# SN32F290 register map
Vendor: SONIX; File version: 2026.10.03
CPU: CM0 r0p0, little endian, no MPU, no FPU, 2 interrupt priority bits
Registers are 32-bit, read-write, reset 0x0 unless marked. A register's access mark holds for its fields unless they carry their own. Offsets are from the block's base; [hi:lo] are bit positions; {n}, {i} and the like mark numbered series; 'fields as' and 'values as' point back to an identical list.

## SN_EBI — External Bus Interface
Base 0x40036000
0x00 CTRL reset 0xF00000 (reset mask 0xFFFFFFF) — Offset:0x0 EBI Control Register
  [2n+48:n+24] BK8080MODE{n} (n=0..3) — Bank{n} 8080 Mode
    0=A1D16_4 (A1D16 mode); 1=A1D8_2 (A1D8 mode)
  [43:20] IDLETIME — Bus idle time
    0=No_58 (No Idle time); {v}=V_{v}T (Idle time={v}*PCLK) (v=1..15)
  [2n+32:n+16] ARDY{n}EN (n=0..3) — ARDY of bank {n} enable bit
    0=Disable_434 (Disable bank {n} ARDY function); 1=Enable_145 (Enable bank {n} ARDY function)
  [2n+24:n+12] BC{n}EN (n=0..3) — Byte control of bank {n} enable bit
    0=Disable_434 (Disable byte control of bank {n}); 1=Enable_145 (Enable byte control of bank {n})
  [2n+16:n+8] BANK{n}EN (n=0..3) — EBI bank {n} enable bit
    0=Disable_434 (Disable bank {n}); 1=Enable_145 (Enable bank {n})
  [4n+1:2n] MODE{n} (n=0..3) — EBI bank {n} access mode
    0=AnD8_4 (AnD8 mode); 1=AnD16_4 (AnD16 mode); 2=AnD16ALE_2 (AnD16ALE mode); 3=V_8080_2 (8080 mode)
0x04 ALCTRL (reset mask 0xFFFF) — Offset:0x4 EBI Address Latch Control Register
  [8n+3:4n] AL{n} (n=0..3) — Bank {n} address length=AL{n}+16
    0=V_0000b_19 (AL{n}=0); 1=V_0001b_14 (AL{n}=1); 10=V_1010b_2 (AL{n}=10); 11=V_1011b_18 (AL{n}=10); 12=V_1100b_24 (AL{n}=10); 13=V_1101b (AL{n}=10); 14=V_1110b_12 (AL{n}=10); 15=V_1111b_28 (AL{n}=10); 2=V_0010b_12 (AL{n}=2); 3=V_0011b_12 (AL{n}=3); 4=V_0100b_7 (AL{n}=4); 5=V_0101b_14 (AL{n}=5); 6=V_0110b_4 (AL{n}=6); 7=V_0111b_5 (AL{n}=7); 8=V_1000b_17 (AL{n}=8); 9=V_1001b (AL{n}=9)
0x08 STATUS reset 0x10 (reset mask 0x111) — Offset:0x8 EBI Status Register
  [16:8] EBINSRST — EBI State machine reset
    0=Normal_2 (Normal mode); 1=Reset_V (Reset EBI state machine)
  [8:4] EBIARDY ro — EBI Asynchronous Ready status
    0=Inactive (EBI_ARDY is inactive); 1=Active (EBI_ARDY is active)
  [0] EBIBUSY ro
    0=Idle_6 (EBI is idle); 1=Busy_5 (EBI is busy)
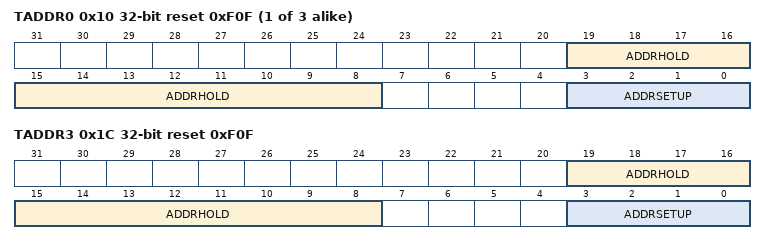
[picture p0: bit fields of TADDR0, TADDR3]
{0x10+4i} TADDR{i} reset 0xF0F (reset mask 0xF0F) (i=0..2) — Offset:{0x10+4i} EBI Address Timing Register {i}
  [19:8] ADDRHOLD — Address Hold time
    0=V_0000b_19 (No Hold time); 1=V_0001b_14 (1*PCLK); 10=V_1010b_2 (10*PCLK); 11=V_1011b_18 (11*PCLK); 12=V_1100b_24 (12*PCLK); 13=V_1101b (13*PCLK); 14=V_1110b_12 (14*PCLK); 15=V_1111b_28 (15*PCLK); 2=V_0010b_12 (2*PCLK); 3=V_0011b_12 (3*PCLK); 4=V_0100b_7 (4*PCLK); 5=V_0101b_14 (5*PCLK); 6=V_0110b_4 (6*PCLK); 7=V_0111b_5 (7*PCLK); 8=V_1000b_17 (8*PCLK); 9=V_1001b (9*PCLK)
  [3:0] ADDRSETUP — Address Setup time
    0=V_0000b_19 (1*PCLK); 1=V_0001b_14 (1*PCLK); 10=V_1010b_2 (10*PCLK); 11=V_1011b_18 (11*PCLK); 12=V_1100b_24 (12*PCLK); 13=V_1101b (13*PCLK); 14=V_1110b_12 (14*PCLK); 15=V_1111b_28 (15*PCLK); 2=V_0010b_12 (2*PCLK); 3=V_0011b_12 (3*PCLK); 4=V_0100b_7 (4*PCLK); 5=V_0101b_14 (5*PCLK); 6=V_0110b_4 (6*PCLK); 7=V_0111b_5 (7*PCLK); 8=V_1000b_17 (8*PCLK); 9=V_1001b (9*PCLK)
0x1C TADDR3 reset 0xF0F (reset mask 0xF0F) — Offset:0x1C EBI Address Timing Register 3
  [19:8] ADDRHOLD — Address Hold time
    0=V_0000b_19 (No address hold time); 1=V_0001b_14 (1*PCLK); 10=V_1010b_2 (10*PCLK); 11=V_1011b_18 (11*PCLK); 12=V_1100b_24 (12*PCLK); 13=V_1101b (13*PCLK); 14=V_1110b_12 (14*PCLK); 15=V_1111b_28 (15*PCLK); 2=V_0010b_12 (2*PCLK); 3=V_0011b_12 (3*PCLK); 4=V_0100b_7 (4*PCLK); 5=V_0101b_14 (5*PCLK); 6=V_0110b_4 (6*PCLK); 7=V_0111b_5 (7*PCLK); 8=V_1000b_17 (8*PCLK); 9=V_1001b (9*PCLK)
  [3:0] ADDRSETUP — Address Setup time
    values as TADDR0.ADDRSETUP
{0x20+4i} TREAD{i} reset 0xF3F0F (reset mask 0xF3F0F) (i=0..3) — Offset:{0x20+4i} EBI Read Timing Register {i}
  [35:16] RDHOLD — Read Hold time
    0=V_0000b_19 (No read hold time); 1=V_0001b_14 (1*PCLK); 10=V_1010b_2 (10*PCLK); 11=V_1011b_18 (11*PCLK); 12=V_1100b_24 (12*PCLK); 13=V_1101b (13*PCLK); 14=V_1110b_12 (14*PCLK); 15=V_1111b_28 (15*PCLK); 2=V_0010b_12 (2*PCLK); 3=V_0011b_12 (3*PCLK); 4=V_0100b_7 (4*PCLK); 5=V_0101b_14 (5*PCLK); 6=V_0110b_4 (6*PCLK); 7=V_0111b_5 (7*PCLK); 8=V_1000b_17 (8*PCLK); 9=V_1001b (9*PCLK)
  [21:8] RDSTRB — Read Strobe time
    0=V_000000b_7 (1*PCLK); 1=V_000001b_7 (1*PCLK); 10=V_001010b (10*PCLK); 11=V_001011b_8 (11*PCLK); 12=V_001100b_6 (12*PCLK); 13=V_001101b (13*PCLK); 14=V_001110b (14*PCLK); 15=V_001111b_8 (15*PCLK); 16=V_010000b (16*PCLK); 17=V_010001b_5 (17*PCLK); 18=V_010010b (18*PCLK); 19=V_010011b_2 (19*PCLK); 2=V_000010b_3 (2*PCLK); 20=V_010100b_3 (20*PCLK); 21=V_010101b_4 (21*PCLK); 22=V_010110b_8 (22*PCLK); 23=V_010111b_3 (23*PCLK); 24=V_011000b_6 (24*PCLK); 25=V_011001b_5 (25*PCLK); 26=V_011010b_5 (26*PCLK); 27=V_011011b_7 (27*PCLK); 28=V_011100b_4 (28*PCLK); 29=V_011101b_6 (29*PCLK); 3=V_000011b_3 (3*PCLK); 30=V_011110b_7 (30*PCLK); 31=V_011111b_7 (31*PCLK); 32=V_100000b_8 (32*PCLK); 33=V_100001b_3 (33*PCLK); 34=V_100010b_6 (34*PCLK); 35=V_100011b_8 (35*PCLK); 36=V_100100b_5 (36*PCLK); 37=V_100101b_5 (37*PCLK); 38=V_100110b_8 (38*PCLK); 39=V_100111b_3 (39*PCLK); 4=V_000100b_2 (4*PCLK); 40=V_101000b_3 (40*PCLK); 41=V_101001b_8 (41*PCLK); 42=V_101010b_7 (42*PCLK); 43=V_101011b_3 (43*PCLK); 44=V_101100b_4 (44*PCLK); 45=V_101101b_3 (45*PCLK); 46=V_101110b (46*PCLK); 47=V_101111b_6 (47*PCLK); 48=V_110000b_5 (48*PCLK); 49=V_110001b (49*PCLK); 5=V_000101b_2 (5*PCLK); 50=V_110010b_8 (50*PCLK); 51=V_110011b_8 (51*PCLK); 52=V_110100b_3 (52*PCLK); 53=V_110101b_3 (53*PCLK); 54=V_110110b_2 (54*PCLK); 55=V_110111b_2 (55*PCLK); 56=V_111000b_5 (56*PCLK); 57=V_111001b_2 (57*PCLK); 58=V_111010b_6 (58*PCLK); 59=V_111011b_5 (59*PCLK); 6=V_000110b_2 (6*PCLK); 60=V_111100b (60*PCLK); 61=V_111101b_8 (61*PCLK); 62=V_111110b_7 (62*PCLK); 63=V_111111b_2 (63*PCLK); 7=V_000111b_4 (7*PCLK); 8=V_001000b_6 (8*PCLK); 9=V_001001b_8 (9*PCLK)
  [3:0] RDSETUP — Read Setup time
    0=V_0000b_19 (No read setup time); 1=V_0001b_14 (1*PCLK); 10=V_1010b_2 (10*PCLK); 11=V_1011b_18 (11*PCLK); 12=V_1100b_24 (12*PCLK); 13=V_1101b (13*PCLK); 14=V_1110b_12 (14*PCLK); 15=V_1111b_28 (15*PCLK); 2=V_0010b_12 (2*PCLK); 3=V_0011b_12 (3*PCLK); 4=V_0100b_7 (4*PCLK); 5=V_0101b_14 (5*PCLK); 6=V_0110b_4 (6*PCLK); 7=V_0111b_5 (7*PCLK); 8=V_1000b_17 (8*PCLK); 9=V_1001b (9*PCLK)
{0x30+4i} TWRITE{i} reset 0xF3F0F (reset mask 0xF3F0F) (i=0..3) — Offset:{0x30+4i} EBI Write Timing Register {i}
  [35:16] WEHOLD — Write Hold time
    0=V_0000b_19 (No write hold time); 1=V_0001b_14 (1*PCLK); 10=V_1010b_2 (10*PCLK); 11=V_1011b_18 (11*PCLK); 12=V_1100b_24 (12*PCLK); 13=V_1101b (13*PCLK); 14=V_1110b_12 (14*PCLK); 15=V_1111b_28 (15*PCLK); 2=V_0010b_12 (2*PCLK); 3=V_0011b_12 (3*PCLK); 4=V_0100b_7 (4*PCLK); 5=V_0101b_14 (5*PCLK); 6=V_0110b_4 (6*PCLK); 7=V_0111b_5 (7*PCLK); 8=V_1000b_17 (8*PCLK); 9=V_1001b (9*PCLK)
  [21:8] WESTRB — Write Strobe time
    values as TREAD0.RDSTRB
  [3:0] WESETUP — Write Setup time
    0=V_0000b_19 (No write setup time); 1=V_0001b_14 (1*PCLK); 10=V_1010b_2 (10*PCLK); 11=V_1011b_18 (11*PCLK); 12=V_1100b_24 (12*PCLK); 13=V_1101b (13*PCLK); 14=V_1110b_12 (14*PCLK); 15=V_1111b_28 (15*PCLK); 2=V_0010b_12 (2*PCLK); 3=V_0011b_12 (3*PCLK); 4=V_0100b_7 (4*PCLK); 5=V_0101b_14 (5*PCLK); 6=V_0110b_4 (6*PCLK); 7=V_0111b_5 (7*PCLK); 8=V_1000b_17 (8*PCLK); 9=V_1001b (9*PCLK)
{0x40+4i} PR{i} (reset mask 0x3F) (i=0..3) — Offset:{0x40+4i} EBI Polarity Register {i}
  [10:5] UBLBPOL ro — Upper Byte and Lower Byte polarity
    0=Active_Low_2 (Upper byte and Lower byte are active low)
  [8:4] ARDYPOL — Asynchronous Ready polarity
    0=Active_Low_2 (ARDY is active low); 1=Active_High_3 (ARDY is active high)
  [6:3] ALEPOL ro — Address Latch polarity
    0=Active_Low_2 (ALE is active low)
  [4:2] WEPOL ro — Write Enable polarity
    0=Active_Low_2 (WE is active low)
  [2:1] OEPOL ro — Output Enable polarity
    0=Active_Low_2 (OE is active low)
  [0] CSPOL ro — Chip Select polarity
    0=Active_Low_2 (CS is active low)
0x50 IE (reset mask 0x3F) — Offset:0x50 EBI Interrupt Enable Register
  [10:5] DMATCIE — DMA transfer complete interrupt enable bit
    0=Disable_434 (Disable DMATC interrupt); 1=Enable_145 (Enable DMATC interrupt)
  [8:4] DMAHTIE — DMA half-transfer interrupt enable bit
    0=Disable_434 (Disable DMAHT interrupt); 1=Enable_145 (Enable DMAHT interrupt)
  [6:3] RWERREN — Interrupt for read/writer error enable bit
    0=Disable_434 (Disable RWERR interrupt); 1=Enable_145 (Enable RWERR interrupt)
  [4:2] SMRSTEN — Interrupt for issuing a transaction during EBI state machine reset period enable bit
    0=Disable_434 (Disable SMRST interrupt); 1=Enable_145 (Enable SMRST interrupt)
  [2:1] ACCDISEN — Interrupt for accessing the disabled bank enable bit
    0=Disable_434 (Disable ACCDIS interrupt); 1=Enable_145 (Enable ACCDIS interrupt)
  [0] ARDYTOEN — EBI asynchronous ready time-out interrupt enable bit
    0=Disable_434 (Disable ARDYTO interrupt); 1=Enable_145 (Enable ARDYTO interrupt)
0x54 RIS ro (reset mask 0x3F) — Offset:0x54 EBI Interrupt Flag Register
  [10:5] DMATCIF — DMA transfer complete flag
    0=No_DMA_transfer_completed; 1=DMA_Transfer_completed (A transfer complete event occurs)
  [8:4] DMAHTIF — DMA half-transfer flag
    0=No_event (No half-transfer event); 1=Half_transfer_event (A half-transfer event occurs)
  [6:3] RWERRIF — EBI read/write error flag
    0=Not_error (Not read/write error); 1=Error_2 (Read/write error)
  [4:2] SMRSTIF — EBI state machine reset flag
    0=Not resetting the EBI state machine; 1=Resetting (EBI is resetting the state machine)
  [2:1] ACCDISIF — EBI accessing the disabled bank flag
    0=Not accessing the disabled bank; 1=Accessing (EBI is accessing the disabled bank)
  [0] ARDYTOIF — EBI asynchronous ready time-out flag
    0=Not_timeout (ARDY Not Timeout); 1=Timeout (ARDY Timeout)
0x58 IC wo (reset mask 0x3F) — Offset:0x58 EBI Interrupt Clear Register
  [10:5] DMATCIC — Select DMA transfer complete flag to be cleared
    0=No_effect_200; 1=Clear_V_150 (Clear DMATCIF flag)
  [8:4] DMAHTIC — Select DMA half-transfer flag to be cleared
    0=No_effect_200; 1=Clear_V_150 (Clear DMAHTIF flag)
  [6:3] RWERRIC — Select RWERRIF flag to be cleared
    0=No_effect_200; 1=Clear_V_150 (Clear RWERRIF flag)
  [4:2] SMRSTIC — Select SMRSTIF flag to be cleared
    0=No_effect_200; 1=Clear_V_150 (Clear SMRSTIF flag)
  [2:1] ACCDISIC — Select ACCDISIF flag to be cleared
    0=No_effect_200; 1=Clear_V_150 (Clear ACCDISIF flag)
  [0] ARDYTOIC — Select ARDYTOIF flag to be cleared
    0=No_effect_200; 1=Clear_V_150 (Clear ARDYIF flag)
0x5C DMACTRL (reset mask 0xF) — Offset:0x5C EBI DMA Control Register
  [5:2] BANKSELECT — EBI Bank n select bits
    {v}=BANK_{v} (EBI Bank {v}) (v=0..3)
  [2:1] SPISELECT — SPIn select bit
    0=SPI0; 1=SPI1
  [0] DMAEN — EBI DMA enable bit
    0=Disable_434 (Disable EBI DMA); 1=Enable_145 (Enable EBI DMA)
0x64 DMACNT — Offset:0x64 DMA Number of data transfer register
  [27:0] CNT — Number of data to DMA RX count transfer
0x68 DMAHTCNT reset 0xFFFFFFF — Offset:0x68 EBI DMA Half-transfer Register
  [27:0] HTCNT — Number of data to DMA RX half count transfer
0x6C CURCNT ro — Offset:0x6C EBI DMA Current Transfer Data Counter Register
  [27:0] CURCNT — Number of data to DMA RX half count transfer
